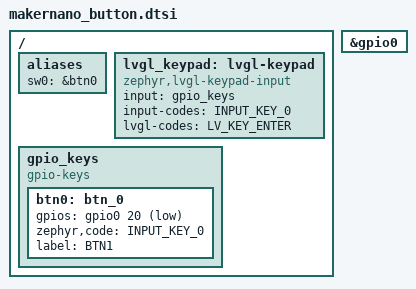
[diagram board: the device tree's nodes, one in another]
/*
 * Copyright (c) 2023 TiaC Systems
 * SPDX-License-Identifier: Apache-2.0
 */

#include <zephyr/dt-bindings/input/input-event-codes.h>
#include <zephyr/dt-bindings/lvgl/lvgl.h>
#include <zephyr/dt-bindings/gpio/gpio.h>

/ {
	aliases {
		sw0 = &btn0;
	};

	lvgl_keypad: lvgl-keypad {
		compatible = "zephyr,lvgl-keypad-input";
		input = <&gpio_keys>;
		input-codes = <INPUT_KEY_0>;
		lvgl-codes = <LV_KEY_ENTER>;
	};

	gpio_keys: gpio_keys {
		compatible = "gpio-keys";
		status = "okay";

		btn0: btn_0 {
			gpios = <&gpio0 20 GPIO_ACTIVE_LOW>;
			zephyr,code = <INPUT_KEY_0>;
			label = "BTN1";
		};
	};
};

&gpio0 {
	status = "okay";
};
